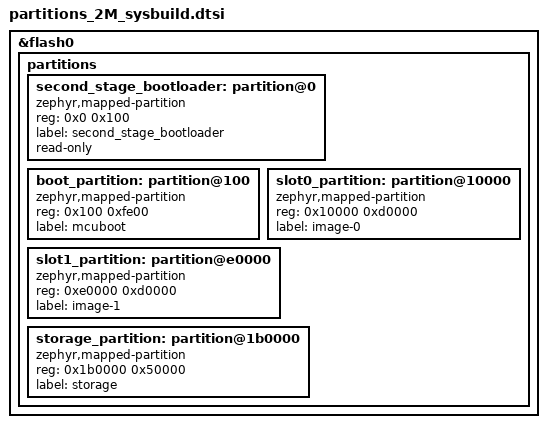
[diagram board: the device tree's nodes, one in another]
/*
 * Copyright (c) 2025 Beechwoods Software, Inc.
 *
 * SPDX-License-Identifier: Apache-2.0
 */

&flash0 {
	status = "okay";

	partitions {
		ranges;
		#address-cells = <0x1>;
		#size-cells = <0x1>;

		second_stage_bootloader: partition@0 {
			compatible = "zephyr,mapped-partition";
			reg = <0x0 0x100>;
			label = "second_stage_bootloader";
			read-only;
		};

		boot_partition: partition@100 {
			compatible = "zephyr,mapped-partition";
			reg = <0x100 0xfe00>;
			label = "mcuboot";
		};

		slot0_partition: partition@10000 {
			compatible = "zephyr,mapped-partition";
			reg = <0x10000 0xd0000>;
			label = "image-0";
		};

		slot1_partition: partition@e0000 {
			compatible = "zephyr,mapped-partition";
			reg = <0xe0000 0xd0000>;
			label = "image-1";
		};

		storage_partition: partition@1b0000 {
			compatible = "zephyr,mapped-partition";
			reg = <0x1b0000 0x50000>;
			label = "storage";
		};
	};
};
